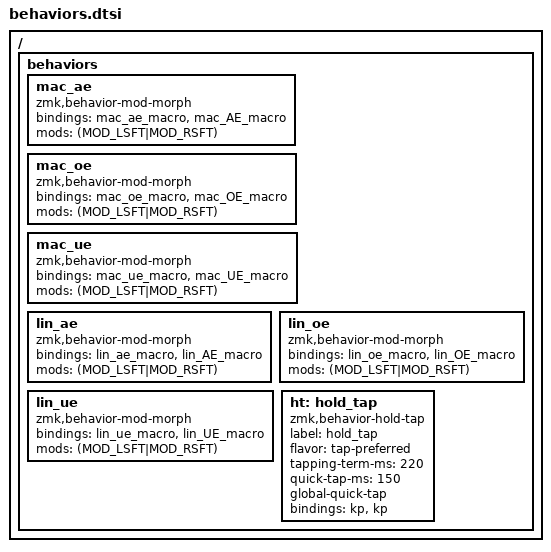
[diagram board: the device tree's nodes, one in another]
/ {
    behaviors {

        mac_ae: mac_ae {
            compatible = "zmk,behavior-mod-morph";
            #binding-cells = <0>;
            bindings = <&mac_ae_macro>, <&mac_AE_macro>;
            mods = <(MOD_LSFT|MOD_RSFT)>;
        };

        mac_oe: mac_oe {
            compatible = "zmk,behavior-mod-morph";
            #binding-cells = <0>;
            bindings = <&mac_oe_macro>, <&mac_OE_macro>;
            mods = <(MOD_LSFT|MOD_RSFT)>;
        };

        mac_ue: mac_ue {
            compatible = "zmk,behavior-mod-morph";
            #binding-cells = <0>;
            bindings = <&mac_ue_macro>, <&mac_UE_macro>;
            mods = <(MOD_LSFT|MOD_RSFT)>;
        };

        lin_ae: lin_ae {
            compatible = "zmk,behavior-mod-morph";
            #binding-cells = <0>;
            bindings = <&lin_ae_macro>, <&lin_AE_macro>;
            mods = <(MOD_LSFT|MOD_RSFT)>;
        };

        lin_oe: lin_oe {
            compatible = "zmk,behavior-mod-morph";
            #binding-cells = <0>;
            bindings = <&lin_oe_macro>, <&lin_OE_macro>;
            mods = <(MOD_LSFT|MOD_RSFT)>;
        };

        lin_ue: lin_ue {
            compatible = "zmk,behavior-mod-morph";
            #binding-cells = <0>;
            bindings = <&lin_ue_macro>, <&lin_UE_macro>;
            mods = <(MOD_LSFT|MOD_RSFT)>;
        };

        ht: hold_tap {
            label = "hold_tap";
            compatible = "zmk,behavior-hold-tap";
            #binding-cells = <2>;
            flavor = "tap-preferred";
            tapping-term-ms = <220>;
            quick-tap-ms = <150>;
            global-quick-tap;
            bindings = <&kp>, <&kp>;
        };

    };
};
